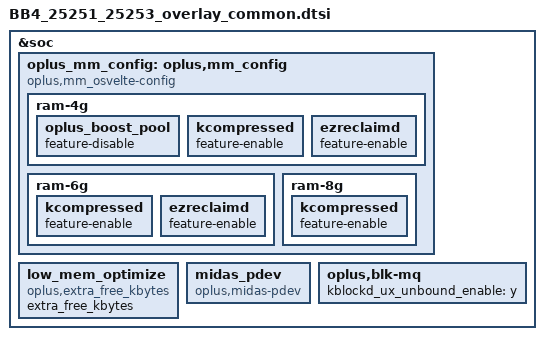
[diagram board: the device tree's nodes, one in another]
#include "fingerprint/uff_sm6225_Baikai-B4_25251_25253.dtsi"
#include "oplus_thermal/bb4_oplus_thermal.dtsi"
#include "tp/BaikalB4_touchpanel.dtsi"

&soc {
	oplus_mm_config: oplus,mm_config {
		compatible = "oplus,mm_osvelte-config";
		ram-4g {
			oplus_boost_pool {
				feature-disable;
			};
			kcompressed {
				feature-enable;
			};
			ezreclaimd {
				feature-enable;
			};
		};
		ram-6g {
			kcompressed {
				feature-enable;
			};
			ezreclaimd {
				feature-enable;
			};
		};
		ram-8g {
			kcompressed {
				feature-enable;
			};
		};
	};
};

&soc {
/* Add for low_mem_optimize */
	low_mem_optimize {
		compatible = "oplus,extra_free_kbytes";
		extra_free_kbytes;
	};
};

&soc {
	midas_pdev {
		compatible = "oplus,midas-pdev";
	};
};

&soc {
	//@Kernel.Storage, 2025/09/16, add for blk-mq.c kblockd_ux_unbound_enable
	oplus,blk-mq {
		kblockd_ux_unbound_enable = "y";
	};
};
